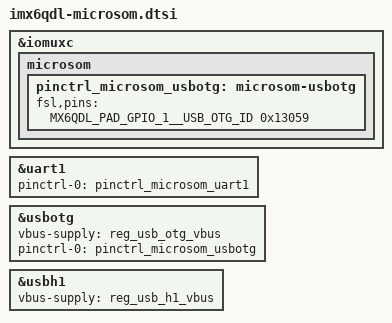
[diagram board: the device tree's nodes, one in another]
/*
 * Copyright (C) 2013,2014 Russell King
 */

&iomuxc {
	microsom {
		pinctrl_microsom_usbotg: microsom-usbotg {
			/*
			 * Similar to pinctrl_usbotg_2, but we want it
			 * pulled down for a fixed host connection.
			 */
			fsl,pins = <MX6QDL_PAD_GPIO_1__USB_OTG_ID 0x13059>;
		};
	};
};

&uart1 {
	pinctrl-names = "default";
	pinctrl-0 = <&pinctrl_microsom_uart1>;
	status = "okay";
};

&usbotg {
	vbus-supply = <&reg_usb_otg_vbus>;
	pinctrl-names = "default";
	pinctrl-0 = <&pinctrl_microsom_usbotg>;
	status = "okay";
};

&usbh1 {
	vbus-supply = <&reg_usb_h1_vbus>;
	status = "okay";
};
